AUTOSAR XML (schema 4-2-2)
package /Components
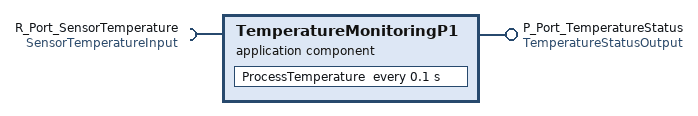
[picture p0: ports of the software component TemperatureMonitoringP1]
  application sw component type TemperatureMonitoringP1
    provide port P_Port_TemperatureStatus: provided-interface=TemperatureStatusOutput
    require port R_Port_SensorTemperature: required-interface=SensorTemperatureInput
    behavior TemperatureMonitoringP1: handle-termination-and-restart=CAN-BE-TERMINATED-AND-RESTARTED
      data received event SensorTemperature_DataReceived: start-on-event=ProcessTemperature
      timing event ProcessTemperature_0p1s_Periodic: start-on-event=ProcessTemperature, period=0.1
      runnable ProcessTemperature
        data-receive-point-by-arguments:
          access VA_SensorTemperature_Read: accessed-variable=R_Port_SensorTemperature.SensorTemperature
        data-send-points:
          access VA_TemperatureStatus_Write: accessed-variable=P_Port_TemperatureStatus.TemperatureStatus
